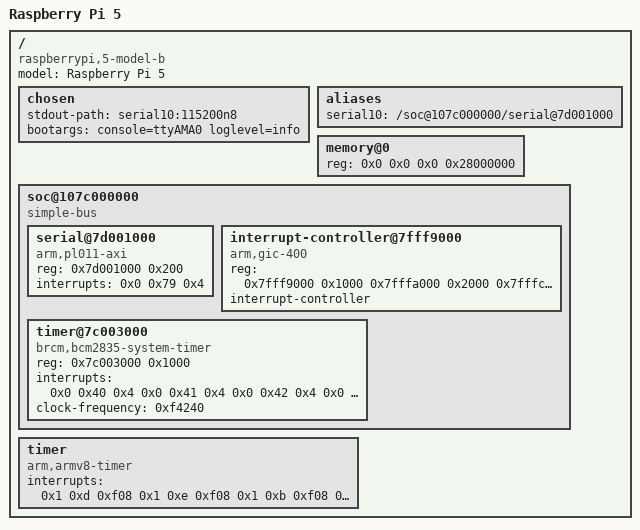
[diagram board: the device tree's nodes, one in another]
// SPDX-License-Identifier: BSD-3-Clause
// Generated by tests/fixtures/pi5/generate.py; values from the official Pi 5 DTB.
/dts-v1/;

/ {
    compatible = "raspberrypi,5-model-b", "brcm,bcm2712";
    model = "Raspberry Pi 5";
    #address-cells = <0x2>;
    #size-cells = <0x2>;
    chosen {
        stdout-path = "serial10:115200n8";
        bootargs = "console=ttyAMA0 loglevel=info";
    };
    aliases {
        serial10 = "/soc@107c000000/serial@7d001000";
    };
    memory@0 {
        device_type = "memory";
        reg = <0x0 0x0 0x0 0x28000000>;
    };
    soc@107c000000 {
        compatible = "simple-bus";
        #address-cells = <0x1>;
        #size-cells = <0x1>;
        ranges = <0x0 0x10 0x0 0x80000000>;
        serial@7d001000 {
            compatible = "arm,pl011-axi", "arm,pl011", "arm,primecell";
            reg = <0x7d001000 0x200>;
            interrupts = <0x0 0x79 0x4>;
            status = "okay";
        };
        interrupt-controller@7fff9000 {
            compatible = "arm,gic-400";
            reg = <0x7fff9000 0x1000 0x7fffa000 0x2000 0x7fffc000 0x2000 0x7fffe000 0x2000>;
            interrupt-controller;
            #interrupt-cells = <0x3>;
        };
        timer@7c003000 {
            compatible = "brcm,bcm2835-system-timer";
            reg = <0x7c003000 0x1000>;
            interrupts = <0x0 0x40 0x4 0x0 0x41 0x4 0x0 0x42 0x4 0x0 0x43 0x4>;
            clock-frequency = <0xf4240>;
        };
    };
    timer {
        compatible = "arm,armv8-timer";
        interrupts = <0x1 0xd 0xf08 0x1 0xe 0xf08 0x1 0xb 0xf08 0x1 0xa 0xf08>;
    };
};
